AUTOSAR XML (schema 4-0-3)
standard types defined: Boolean, UInt16, UInt32, UInt8
package /AUTOSAR_Platform/DataConstrs
  range DC_Boolean: raw 0..1
  range DC_UInt16: raw 0..65535
  range DC_UInt8: raw 0..255
package /PATAC/MSM/ComponentTypes
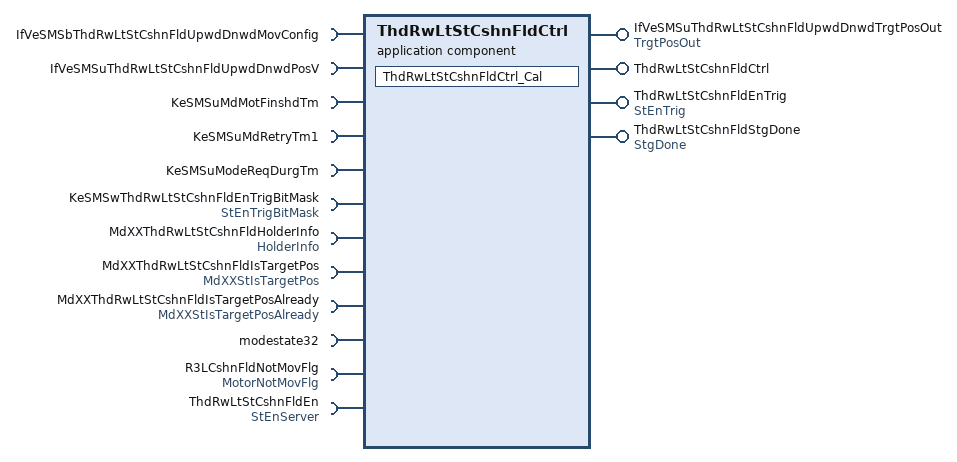
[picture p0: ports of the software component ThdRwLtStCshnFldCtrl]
  application sw component type ThdRwLtStCshnFldCtrl
    4 x provide port:
      IfVeSMSuThdRwLtStCshnFldUpwdDnwdTrgtPosOut: nonqueued-sender-com-spec=data-element=TrgtPosOut/Val, provided-interface=TrgtPosOut
      ThdRwLtStCshnFldCtrl: server-com-spec{operation=Cal, queue-length=1}, provided-interface=ThdRwLtStCshnFldCtrl
      ThdRwLtStCshnFldEnTrig: nonqueued-sender-com-spec{data-element=StEnTrig/Val, init-value=0}, provided-interface=StEnTrig
      ThdRwLtStCshnFldStgDone: nonqueued-sender-com-spec{data-element=StgDone/Val, init-value=0}, provided-interface=StgDone
    12 x require port:
      IfVeSMSbThdRwLtStCshnFldUpwdDnwdMovConfig: nonqueued-receiver-com-spec{data-element=IfVeSMSbThdRwLtStCshnFldUpwdDnwdMovConfig/Val, filter=data-filter-type=ALWAYS, init-value=0}, required-interface=IfVeSMSbThdRwLtStCshnFldUpwdDnwdMovConfig
      IfVeSMSuThdRwLtStCshnFldUpwdDnwdPosV: nonqueued-receiver-com-spec{data-element=IfVeSMSuThdRwLtStCshnFldUpwdDnwdPosV/Val, filter=data-filter-type=ALWAYS, init-value=0}, required-interface=IfVeSMSuThdRwLtStCshnFldUpwdDnwdPosV
      KeSMSuMdMotFinshdTm: parameter-require-com-spec{init-value=0, parameter=KeSMSuMdMotFinshdTm/Val}, required-interface=KeSMSuMdMotFinshdTm
      KeSMSuMdRetryTm1: parameter-require-com-spec{init-value=0, parameter=KeSMSuMdRetryTm1/Val}, required-interface=KeSMSuMdRetryTm1
      KeSMSuModeReqDurgTm: parameter-require-com-spec{init-value=0, parameter=KeSMSuModeReqDurgTm/Val}, required-interface=KeSMSuModeReqDurgTm
      KeSMSwThdRwLtStCshnFldEnTrigBitMask: parameter-require-com-spec{init-value=6153, parameter=StEnTrigBitMask/Val}, required-interface=StEnTrigBitMask
      MdXXThdRwLtStCshnFldHolderInfo: nonqueued-receiver-com-spec{data-element=HolderInfo/Val, filter=data-filter-type=ALWAYS, init-value=0}, required-interface=HolderInfo
      MdXXThdRwLtStCshnFldIsTargetPos: nonqueued-receiver-com-spec{data-element=MdXXStIsTargetPos/Val, filter=data-filter-type=ALWAYS, init-value=0}, required-interface=MdXXStIsTargetPos
      MdXXThdRwLtStCshnFldIsTargetPosAlready: nonqueued-receiver-com-spec{data-element=MdXXStIsTargetPosAlready/Val, filter=data-filter-type=ALWAYS, init-value=0}, required-interface=MdXXStIsTargetPosAlready
      modestate32: nonqueued-receiver-com-spec{data-element=modestate32/Val, filter=data-filter-type=ALWAYS, init-value=0}, required-interface=modestate32
      R3LCshnFldNotMovFlg: nonqueued-receiver-com-spec{data-element=MotorNotMovFlg/Val, filter=data-filter-type=ALWAYS, init-value=0}, required-interface=MotorNotMovFlg
      ThdRwLtStCshnFldEn: required-com-specs=[Clear, Get, Set], required-interface=StEnServer
    behavior ThdRwLtStCshnFldCtrl_InternalBehavior
      operation invoked event OIT_ThdRwLtStCshnFldCtrl_Cal_ThdRwLtStCshnFldCtrl_Cal: start-on-event=ThdRwLtStCshnFldCtrl_Cal, operation=ThdRwLtStCshnFldCtrl.Cal
      runnable ThdRwLtStCshnFldCtrl_Cal
        data-receive-point-by-arguments:
          7 x access:
            REC_IfVeSMSbThdRwLtStCshnFldUpwdDnwdMovConfig_Val: accessed-variable=IfVeSMSbThdRwLtStCshnFldUpwdDnwdMovConfig.Val
            REC_IfVeSMSuThdRwLtStCshnFldUpwdDnwdPosV_Val: accessed-variable=IfVeSMSuThdRwLtStCshnFldUpwdDnwdPosV.Val
            REC_MdXXThdRwLtStCshnFldHolderInfo_Val: accessed-variable=MdXXThdRwLtStCshnFldHolderInfo.Val
            REC_MdXXThdRwLtStCshnFldIsTargetPos_Val: accessed-variable=MdXXThdRwLtStCshnFldIsTargetPos.Val
            REC_MdXXThdRwLtStCshnFldIsTargetPosAlready_Val: accessed-variable=MdXXThdRwLtStCshnFldIsTargetPosAlready.Val
            REC_modestate32_Val: accessed-variable=modestate32.Val
            REC_R3LCshnFldNotMovFlg_Val: accessed-variable=R3LCshnFldNotMovFlg.Val
        data-send-points:
          access SEND_IfVeSMSuThdRwLtStCshnFldUpwdDnwdTrgtPosOut_Val: accessed-variable=IfVeSMSuThdRwLtStCshnFldUpwdDnwdTrgtPosOut.Val
          access SEND_ThdRwLtStCshnFldEnTrig_Val: accessed-variable=ThdRwLtStCshnFldEnTrig.Val
          access SEND_ThdRwLtStCshnFldStgDone_Val: accessed-variable=ThdRwLtStCshnFldStgDone.Val
        4 x parameter access:
          PA_KeSMSuMdMotFinshdTm_Val: accessed-parameter=KeSMSuMdMotFinshdTm.Val
          PA_KeSMSuMdRetryTm1_Val: accessed-parameter=KeSMSuMdRetryTm1.Val
          PA_KeSMSuModeReqDurgTm_Val: accessed-parameter=KeSMSuModeReqDurgTm.Val
          PA_KeSMSwThdRwLtStCshnFldEnTrigBitMask_Val: accessed-parameter=KeSMSwThdRwLtStCshnFldEnTrigBitMask.Val
        sync call SC_ThdRwLtStCshnFldEn_Get: operation=ThdRwLtStCshnFldEn.Get, timeout=0
  swc implementation ThdRwLtStCshnFldCtrl_Implementation: behavior=ThdRwLtStCshnFldCtrl_InternalBehavior
    code-descriptors:
      code Default: artifact-descriptors=autosar-engineering-object={short-label=Default, category=SWSRC}
package /PATAC/MSM/ModeAdjust/CalPortInterface
  parameter interface KeSMSuMdMotFinshdTm
    parameter data prototype Val: sw-calibration-access=READ-WRITE, type=UInt16
  parameter interface KeSMSuModeReqDurgTm
    parameter data prototype Val: sw-calibration-access=READ-WRITE, type=UInt16
  parameter interface StEnTrigBitMask
    parameter data prototype Val: sw-calibration-access=READ-WRITE, type=UInt32
package /PATAC/MSM/ModeAdjust/Interfaces
  sender receiver interface IfVeSMSuThdRwLtStCshnFldUpwdDnwdPosV: invalidation-policy{data-element=IfVeSMSuThdRwLtStCshnFldUpwdDnwdPosV/Val, handle-invalid=DONT-INVALIDATE}
    data Val: type=Boolean
package /PATAC/MSM/ModeAdjust/PortInterface
  client server interface StEnServer
    operation Clear
      arg data: type=UInt8, direction=IN, server-argument-impl-policy=USE-ARGUMENT-TYPE
    operation Get
      arg data: type=UInt32, direction=OUT, server-argument-impl-policy=USE-ARGUMENT-TYPE
    operation Set
      arg data: type=UInt8, direction=IN, server-argument-impl-policy=USE-ARGUMENT-TYPE
  client server interface ThdRwLtStCshnFldCtrl
    operation Cal
  8 x sender receiver interface:
    HolderInfo: invalidation-policy{data-element=HolderInfo/Val, handle-invalid=DONT-INVALIDATE}
      data Val: type=UInt32
    MdXXStIsTargetPos: invalidation-policy{data-element=MdXXStIsTargetPos/Val, handle-invalid=DONT-INVALIDATE}
      data Val: type=UInt32
    MdXXStIsTargetPosAlready: invalidation-policy{data-element=MdXXStIsTargetPosAlready/Val, handle-invalid=DONT-INVALIDATE}
      data Val: type=UInt32
    modestate32: invalidation-policy{data-element=modestate32/Val, handle-invalid=DONT-INVALIDATE}
      data Val: type=UInt32
    MotorNotMovFlg: invalidation-policy{data-element=MotorNotMovFlg/Val, handle-invalid=DONT-INVALIDATE}
      data Val: type=Boolean
    StEnTrig: invalidation-policy{data-element=StEnTrig/Val, handle-invalid=DONT-INVALIDATE}
      data Val: type=Boolean
    StgDone: invalidation-policy{data-element=StgDone/Val, handle-invalid=DONT-INVALIDATE}
      data Val: type=Boolean
    TrgtPosOut: invalidation-policy{data-element=TrgtPosOut/Val, handle-invalid=DONT-INVALIDATE}
      data Val: type=Boolean
package /PATAC/MSM/PortInterfaces
  parameter interface KeSMSuMdRetryTm1
    parameter data prototype Val: sw-calibration-access=READ-WRITE, type=UInt8
  sender receiver interface IfVeSMSbThdRwLtStCshnFldUpwdDnwdMovConfig: invalidation-policy{data-element=IfVeSMSbThdRwLtStCshnFldUpwdDnwdMovConfig/Val, handle-invalid=DONT-INVALIDATE}
    data Val: type=Boolean
